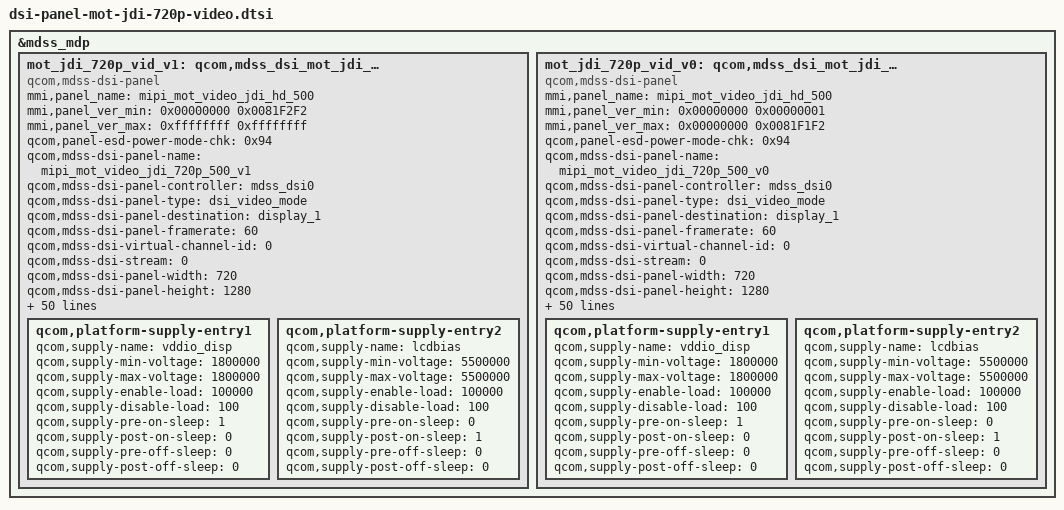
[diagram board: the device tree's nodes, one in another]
/* Copyright (c) 2014, Motorola Mobility LLC. All rights reserved.
 *
 * This program is free software; you can redistribute it and/or modify
 * it under the terms of the GNU General Public License version 2 and
 * only version 2 as published by the Free Software Foundation.
 *
 * This program is distributed in the hope that it will be useful,
 * but WITHOUT ANY WARRANTY; without even the implied warranty of
 * MERCHANTABILITY or FITNESS FOR A PARTICULAR PURPOSE.  See the
 * GNU General Public License for more details.
 */

&mdss_mdp {
	mot_jdi_720p_vid_v1: qcom,mdss_dsi_mot_jdi_720p_video_v1 {
		compatible = "qcom,mdss-dsi-panel";
		status = "ok";
		mmi,panel_name = "mipi_mot_video_jdi_hd_500";
		mmi,panel_ver_min = <0x00000000 0x0081F2F2>;
		mmi,panel_ver_max = <0xffffffff 0xffffffff>;
		qcom,panel-esd-power-mode-chk = <0x94>;

		qcom,mdss-dsi-panel-name = "mipi_mot_video_jdi_720p_500_v1";
		qcom,mdss-dsi-panel-controller = <&mdss_dsi0>;
		qcom,mdss-dsi-panel-type = "dsi_video_mode";
		qcom,mdss-dsi-panel-destination = "display_1";
		qcom,mdss-dsi-panel-framerate = <60>;
		qcom,mdss-dsi-virtual-channel-id = <0>;
		qcom,mdss-dsi-stream = <0>;
		qcom,mdss-dsi-panel-width = <720>;
		qcom,mdss-dsi-panel-height = <1280>;
		qcom,mdss-pan-physical-width-dimension = <62>;
		qcom,mdss-pan-physical-height-dimension = <110>;
		qcom,mdss-dsi-panel-clockrate = <421729920>;
		qcom,mdss-dsi-h-front-porch = <48>;
		qcom,mdss-dsi-h-back-porch = <68>;
		qcom,mdss-dsi-h-pulse-width = <8>;
		qcom,mdss-dsi-h-sync-skew = <0>;
		qcom,mdss-dsi-v-back-porch = <50>;
		qcom,mdss-dsi-v-front-porch = <52>;
		qcom,mdss-dsi-v-pulse-width = <6>;
		qcom,mdss-dsi-h-left-border = <0>;
		qcom,mdss-dsi-h-right-border = <0>;
		qcom,mdss-dsi-v-top-border = <0>;
		qcom,mdss-dsi-v-bottom-border = <0>;
		qcom,mdss-dsi-bpp = <24>;
		qcom,mdss-dsi-underflow-color = <0xff>;
		qcom,mdss-dsi-border-color = <0>;
		qcom,splash-no-solid-fill;

		qcom,mdss-dsi-on-command = [
			29 01 00 00 00 00 04 FF 12 82 01	/* Start of enabling Access Command1 */
			23 01 00 00 00 00 02 00 80		/* End of enabling Access Command1 */
			23 01 00 00 00 00 03 FF 12 82		/* Start of enabling Orise Command */
			23 01 00 00 00 00 02 00 00
			23 01 00 00 00 00 02 00 B0		/* End of enabling Orise Command */
			29 01 00 00 00 00 05 CA 01 01 5F 44	/* Set PWM frequency to 31.25k Hz*/
			05 01 00 00 78 00 02 11 00		/* Exit sleep */
			15 01 00 00 00 00 02 51 E2		/* Brightness */
			15 01 00 00 00 00 02 53 2C		/* CTRL Display */
			15 01 00 00 00 00 02 5E CD		/* Min CABC Brightness */
			15 01 00 00 00 00 02 55 01		/* CABC Effect */
			05 01 00 00 00 00 02 29 00];		/* Display on */

		qcom,mdss-dsi-off-command = [
			05 01 00 00 78 00 02 28 00
			05 01 00 00 46 00 02 10 00];

		qcom,mdss-dsi-on-command-state = "dsi_lp_mode";
		qcom,mdss-dsi-off-command-state = "dsi_hs_mode";
		qcom,mdss-dsi-cabc-ui-command = [
			15 01 00 00 20 00 02 5E 90
			15 01 00 00 20 00 02 5E 94
			15 01 00 00 20 00 02 5E 98
			15 01 00 00 20 00 02 5E 9C
			15 01 00 00 20 00 02 5E A0
			15 01 00 00 20 00 02 5E A4
			15 01 00 00 20 00 02 5E A8
			15 01 00 00 20 00 02 5E AC
			15 01 00 00 20 00 02 5E B0
			15 01 00 00 20 00 02 5E B4
			15 01 00 00 20 00 02 5E B8
			15 01 00 00 20 00 02 5E BC
			15 01 00 00 20 00 02 5E C0
			15 01 00 00 20 00 02 5E C4
			15 01 00 00 20 00 02 5E C8
			15 01 00 00 20 00 02 5E CD
			15 01 00 00 00 00 02 55 01];
		qcom,mdss-dsi-cabc-mv-command = [
			15 01 00 00 20 00 02 55 03
			15 01 00 00 20 00 02 5E C8
			15 01 00 00 20 00 02 5E C4
			15 01 00 00 20 00 02 5E C0
			15 01 00 00 20 00 02 5E BC
			15 01 00 00 20 00 02 5E B8
			15 01 00 00 20 00 02 5E B4
			15 01 00 00 20 00 02 5E B0
			15 01 00 00 20 00 02 5E AC
			15 01 00 00 20 00 02 5E A8
			15 01 00 00 20 00 02 5E A4
			15 01 00 00 20 00 02 5E A0
			15 01 00 00 20 00 02 5E 9C
			15 01 00 00 20 00 02 5E 98
			15 01 00 00 20 00 02 5E 94
			15 01 00 00 20 00 02 5E 90
			15 01 00 00 20 00 02 5E 8C];
		qcom,mdss-dsi-hbm-off-brightness = <256>;
		qcom,mdss-dsi-hbm-on-brightness = <257>;
		qcom,mdss-dsi-h-sync-pulse = <1>;
		qcom,mdss-dsi-traffic-mode = "burst_mode";
		qcom,mdss-dsi-bllp-eof-power-mode;
		qcom,mdss-dsi-bllp-power-mode;
		qcom,mdss-dsi-lane-0-state;
		qcom,mdss-dsi-lane-1-state;
		qcom,mdss-dsi-lane-2-state;
		qcom,mdss-dsi-lane-3-state;
		qcom,mdss-dsi-panel-timings = [7B 1A 10 00 3E 42 16 1E 15 03 04 00];
		qcom,mdss-dsi-t-clk-post = <0x04>;
		qcom,mdss-dsi-t-clk-pre = <0x1A>;
		qcom,mdss-dsi-bl-min-level = <1>;
		qcom,mdss-dsi-bl-max-level = <255>;
		qcom,mdss-dsi-dma-trigger = "trigger_sw";
		qcom,mdss-dsi-mdp-trigger = "none";
		qcom,mdss-dsi-bl-pmic-control-type = "bl_ctrl_wled";

		qcom,panel-en-reset-sequence = <1 21>, <0 1>, <1 5>;
		qcom,panel-dis-reset-sequence = <0 15>;

		qcom,platform-supply-entry1 {
			qcom,supply-name = "vddio_disp";
			qcom,supply-min-voltage = <1800000>;
			qcom,supply-max-voltage = <1800000>;
			qcom,supply-enable-load = <100000>;
			qcom,supply-disable-load = <100>;
			qcom,supply-pre-on-sleep = <1>;
			qcom,supply-post-on-sleep = <0>;
			qcom,supply-pre-off-sleep = <0>;
			qcom,supply-post-off-sleep = <0>;
		};
		qcom,platform-supply-entry2 {
			qcom,supply-name = "lcdbias";
			qcom,supply-min-voltage = <5500000>;
			qcom,supply-max-voltage = <5500000>;
			qcom,supply-enable-load = <100000>;
			qcom,supply-disable-load = <100>;
			qcom,supply-pre-on-sleep = <0>;
			qcom,supply-post-on-sleep = <1>;
			qcom,supply-pre-off-sleep = <0>;
			qcom,supply-post-off-sleep = <0>;
		};
	};

	mot_jdi_720p_vid_v0: qcom,mdss_dsi_mot_jdi_720p_video_v0 {
		compatible = "qcom,mdss-dsi-panel";
		status = "ok";
		mmi,panel_name = "mipi_mot_video_jdi_hd_500";
		mmi,panel_ver_min = <0x00000000 0x00000001>;
		mmi,panel_ver_max = <0x00000000 0x0081F1F2>;
		qcom,panel-esd-power-mode-chk = <0x94>;

		qcom,mdss-dsi-panel-name = "mipi_mot_video_jdi_720p_500_v0";
		qcom,mdss-dsi-panel-controller = <&mdss_dsi0>;
		qcom,mdss-dsi-panel-type = "dsi_video_mode";
		qcom,mdss-dsi-panel-destination = "display_1";
		qcom,mdss-dsi-panel-framerate = <60>;
		qcom,mdss-dsi-virtual-channel-id = <0>;
		qcom,mdss-dsi-stream = <0>;
		qcom,mdss-dsi-panel-width = <720>;
		qcom,mdss-dsi-panel-height = <1280>;
		qcom,mdss-pan-physical-width-dimension = <62>;
		qcom,mdss-pan-physical-height-dimension = <110>;
		qcom,mdss-dsi-panel-clockrate = <421729920>;
		qcom,mdss-dsi-h-front-porch = <48>;
		qcom,mdss-dsi-h-back-porch = <68>;
		qcom,mdss-dsi-h-pulse-width = <8>;
		qcom,mdss-dsi-h-sync-skew = <0>;
		qcom,mdss-dsi-v-back-porch = <50>;
		qcom,mdss-dsi-v-front-porch = <52>;
		qcom,mdss-dsi-v-pulse-width = <6>;
		qcom,mdss-dsi-h-left-border = <0>;
		qcom,mdss-dsi-h-right-border = <0>;
		qcom,mdss-dsi-v-top-border = <0>;
		qcom,mdss-dsi-v-bottom-border = <0>;
		qcom,mdss-dsi-bpp = <24>;
		qcom,mdss-dsi-underflow-color = <0xff>;
		qcom,mdss-dsi-border-color = <0>;
		qcom,splash-no-solid-fill;

		qcom,mdss-dsi-on-command = [
			29 01 00 00 00 00 04 FF 12 82 01	/* Start of enabling Access Command1 */
			23 01 00 00 00 00 02 00 80		/* End of enabling Access Command1 */
			23 01 00 00 00 00 03 FF 12 82		/* Start of enabling Orise Command */
			23 01 00 00 00 00 02 00 00
			23 01 00 00 00 00 02 00 B0		/* End of enabling Orise Command */
			29 01 00 00 00 00 05 CA 01 01 5F 44	/* Set PWM frequency to 31.25k Hz*/
			05 01 00 00 78 00 02 11 00		/* Exit sleep */
			15 01 00 00 00 00 02 51 FF		/* Brightness */
			15 01 00 00 00 00 02 53 2C		/* CTRL Display */
			15 01 00 00 00 00 02 5E E8		/* Min CABC Brightness */
			15 01 00 00 00 00 02 55 01		/* CABC Effect */
			05 01 00 00 00 00 02 29 00];		/* Display on */

		qcom,mdss-dsi-off-command = [
			05 01 00 00 78 00 02 28 00
			05 01 00 00 46 00 02 10 00];

		qcom,mdss-dsi-on-command-state = "dsi_lp_mode";
		qcom,mdss-dsi-off-command-state = "dsi_hs_mode";
		qcom,mdss-dsi-cabc-ui-command = [
			15 01 00 00 20 00 02 5E AC
			15 01 00 00 20 00 02 5E B0
			15 01 00 00 20 00 02 5E B4
			15 01 00 00 20 00 02 5E B8
			15 01 00 00 20 00 02 5E BC
			15 01 00 00 20 00 02 5E C0
			15 01 00 00 20 00 02 5E C4
			15 01 00 00 20 00 02 5E C8
			15 01 00 00 20 00 02 5E CC
			15 01 00 00 20 00 02 5E D0
			15 01 00 00 20 00 02 5E D4
			15 01 00 00 20 00 02 5E D8
			15 01 00 00 20 00 02 5E DC
			15 01 00 00 20 00 02 5E E0
			15 01 00 00 20 00 02 5E E4
			15 01 00 00 20 00 02 5E E8
			15 01 00 00 00 00 02 55 01];
		qcom,mdss-dsi-cabc-mv-command = [
			15 01 00 00 20 00 02 55 03
			15 01 00 00 20 00 02 5E E4
			15 01 00 00 20 00 02 5E E0
			15 01 00 00 20 00 02 5E DC
			15 01 00 00 20 00 02 5E D8
			15 01 00 00 20 00 02 5E D4
			15 01 00 00 20 00 02 5E D0
			15 01 00 00 20 00 02 5E CC
			15 01 00 00 20 00 02 5E C8
			15 01 00 00 20 00 02 5E C4
			15 01 00 00 20 00 02 5E C0
			15 01 00 00 20 00 02 5E BC
			15 01 00 00 20 00 02 5E B8
			15 01 00 00 20 00 02 5E B4
			15 01 00 00 20 00 02 5E B0
			15 01 00 00 20 00 02 5E AC
			15 01 00 00 00 00 02 5E A8];
		qcom,mdss-dsi-hbm-off-brightness = <256>;
		qcom,mdss-dsi-hbm-on-brightness = <257>;
		qcom,mdss-dsi-h-sync-pulse = <1>;
		qcom,mdss-dsi-traffic-mode = "burst_mode";
		qcom,mdss-dsi-bllp-eof-power-mode;
		qcom,mdss-dsi-bllp-power-mode;
		qcom,mdss-dsi-lane-0-state;
		qcom,mdss-dsi-lane-1-state;
		qcom,mdss-dsi-lane-2-state;
		qcom,mdss-dsi-lane-3-state;
		qcom,mdss-dsi-panel-timings = [7B 1A 10 00 3E 42 16 1E 15 03 04 00];
		qcom,mdss-dsi-t-clk-post = <0x04>;
		qcom,mdss-dsi-t-clk-pre = <0x1A>;
		qcom,mdss-dsi-bl-min-level = <1>;
		qcom,mdss-dsi-bl-max-level = <255>;
		qcom,mdss-dsi-dma-trigger = "trigger_sw";
		qcom,mdss-dsi-mdp-trigger = "none";
		qcom,mdss-dsi-bl-pmic-control-type = "bl_ctrl_wled";

		qcom,panel-en-reset-sequence = <1 21>, <0 1>, <1 5>;
		qcom,panel-dis-reset-sequence = <0 15>;

		qcom,platform-supply-entry1 {
			qcom,supply-name = "vddio_disp";
			qcom,supply-min-voltage = <1800000>;
			qcom,supply-max-voltage = <1800000>;
			qcom,supply-enable-load = <100000>;
			qcom,supply-disable-load = <100>;
			qcom,supply-pre-on-sleep = <1>;
			qcom,supply-post-on-sleep = <0>;
			qcom,supply-pre-off-sleep = <0>;
			qcom,supply-post-off-sleep = <0>;
		};
		qcom,platform-supply-entry2 {
			qcom,supply-name = "lcdbias";
			qcom,supply-min-voltage = <5500000>;
			qcom,supply-max-voltage = <5500000>;
			qcom,supply-enable-load = <100000>;
			qcom,supply-disable-load = <100>;
			qcom,supply-pre-on-sleep = <0>;
			qcom,supply-post-on-sleep = <1>;
			qcom,supply-pre-off-sleep = <0>;
			qcom,supply-post-off-sleep = <0>;
		};
	};
};
